VERSION ""

NS_ :

BS_:

BU_: XXX EON TMCL_actuator

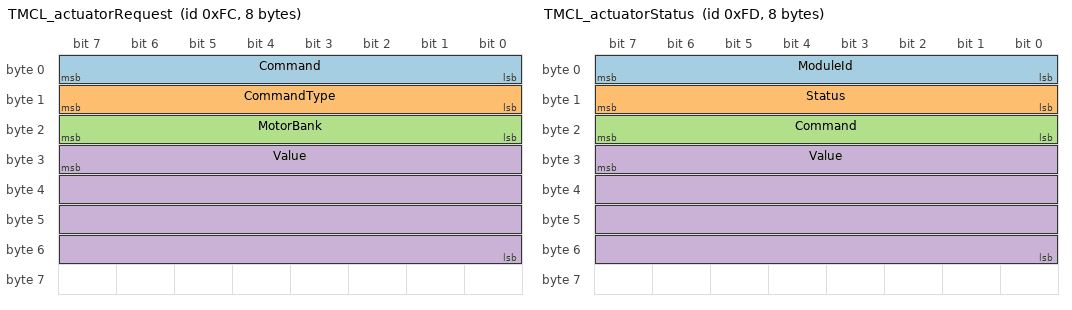
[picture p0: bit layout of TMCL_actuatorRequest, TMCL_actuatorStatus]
BO_ 252 TMCL_actuatorRequest: 8 EON
 SG_ Command : 7|8@0+ (1,0) [0|0] "" Vector__XXX
 SG_ CommandType : 15|8@0+ (1,0) [0|0] "" Vector__XXX
 SG_ MotorBank : 23|8@0+ (1,0) [0|0] "" Vector__XXX
 SG_ Value : 31|32@0- (1,0) [0|0] "" Vector__XXX

BO_ 253 TMCL_actuatorStatus: 8 TMCL_actuator
 SG_ ModuleId : 7|8@0+ (1,0) [0|0] "" Vector__XXX
 SG_ Status : 15|8@0+ (1,0) [0|0] "" Vector__XXX
 SG_ Command : 23|8@0+ (1,0) [0|0] "" Vector__XXX
 SG_ Value : 31|32@0- (1,0) [0|0] "" Vector__XXX

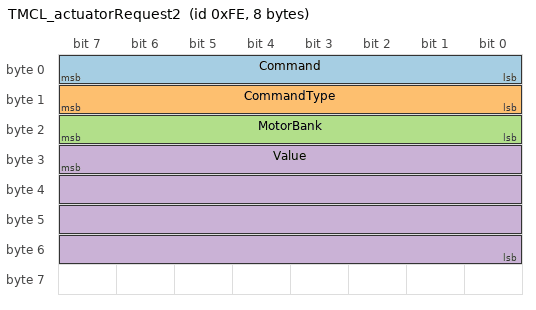
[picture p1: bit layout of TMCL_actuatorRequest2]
BO_ 254 TMCL_actuatorRequest2: 8 EON
 SG_ Command : 7|8@0+ (1,0) [0|0] "" Vector__XXX
 SG_ CommandType : 15|8@0+ (1,0) [0|0] "" Vector__XXX
 SG_ MotorBank : 23|8@0+ (1,0) [0|0] "" Vector__XXX
 SG_ Value : 31|32@0- (1,0) [0|0] "" Vector__XXX

CM_ BU_ TMCL_actuator "Trinamic stepper drivers protocol";
CM_ BO_ 252 "Binary Trinamic Motion Control Language request command";
CM_ SG_ 252 Command "TMCL_Command - e.g SAP Set axis parameter, SGP Setglobal parameter, etc";
CM_ SG_ 252 CommandType "Actuator parameter, e.g. TargetPosition, MaxCurrent";
CM_ SG_ 252 MotorBank "MotorId (or bank id for some commands)";
CM_ SG_ 252 Value "A commanded value according to the CommandType";
